# B6x register map
Vendor: XiaoMan; Series: B6 SOC; File version: 20260307
CPU: CM0+ r0p0, little endian, no MPU, no FPU, 2 interrupt priority bits
Registers are 32-bit, read-write, reset 0x0 unless marked. A register's access mark holds for its fields unless they carry their own. Offsets are from the block's base; [hi:lo] are bit positions.

## RCC — Reset and Clock Control
Base 0x40000000
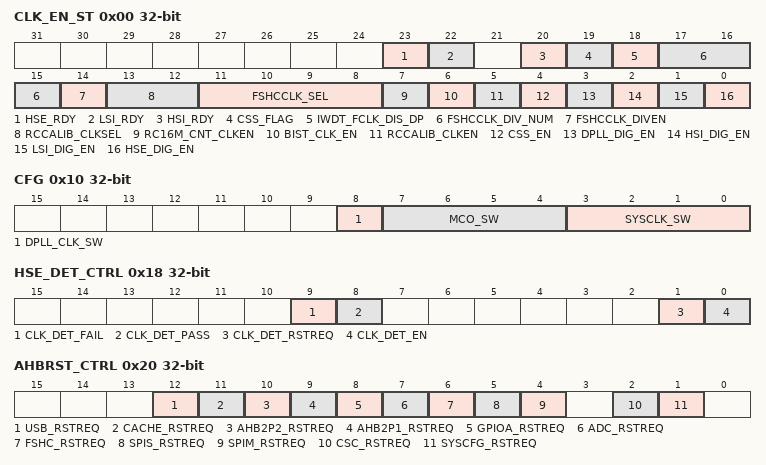
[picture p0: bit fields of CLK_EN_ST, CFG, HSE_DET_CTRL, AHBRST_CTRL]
0x00 CLK_EN_ST
  [23] HSE_RDY
  [22] LSI_RDY
  [20] HSI_RDY
  [19] CSS_FLAG
  [18] IWDT_FCLK_DIS_DP — disable the IWDT function clock (RC32K clock) when chip is in DeepSleep
  [17:15] FSHCCLK_DIV_NUM — div clock = dpll_128m/(fshcclk_div_num + 1)
  [14] FSHCCLK_DIVEN
  [13:12] RCCALIB_CLKSEL
  [11:8] FSHCCLK_SEL — fshc clock source select
  [7] RC16M_CNT_CLKEN
  [6] BIST_CLK_EN
  [5] RCCALIB_CLKEN
  [4] CSS_EN — HSE stable check enable
  [3] DPLL_DIG_EN
  [2] HSI_DIG_EN
  [1] LSI_DIG_EN
  [0] HSE_DIG_EN
0x04 AHBCLK_DIV — ahb_clk = sys_clk/(ahbclk_div+1)
0x08 APB1CLK_DIV — apb1_clk = ahb_clk/(apb1clk_div+1)
0x0C APB2CLK_DIV — apb2_clk = ahb_clk/(apb2clk_div+1)
0x10 CFG
  [8] DPLL_CLK_SW — 0:DPLL clock is use 64M, 1:DPLL clock is use 48M
  [7:4] MCO_SW — clock out source select
  [3:0] SYSCLK_SW — system clock source select
0x14 STCALIB
0x18 HSE_DET_CTRL
  [9] CLK_DET_FAIL
  [8] CLK_DET_PASS
  [1] CLK_DET_RSTREQ — reset the HSE clock detect module
  [0] CLK_DET_EN — HSE clock detect enable
0x1C CHIP_RSTREQ
0x20 AHBRST_CTRL
  [12] USB_RSTREQ, [11] CACHE_RSTREQ, [10] AHB2P2_RSTREQ, [9] AHB2P1_RSTREQ, [8] GPIOA_RSTREQ, [7] ADC_RSTREQ, [6] FSHC_RSTREQ, [5] SPIS_RSTREQ, [4] SPIM_RSTREQ, [2] CSC_RSTREQ, [1] SYSCFG_RSTREQ
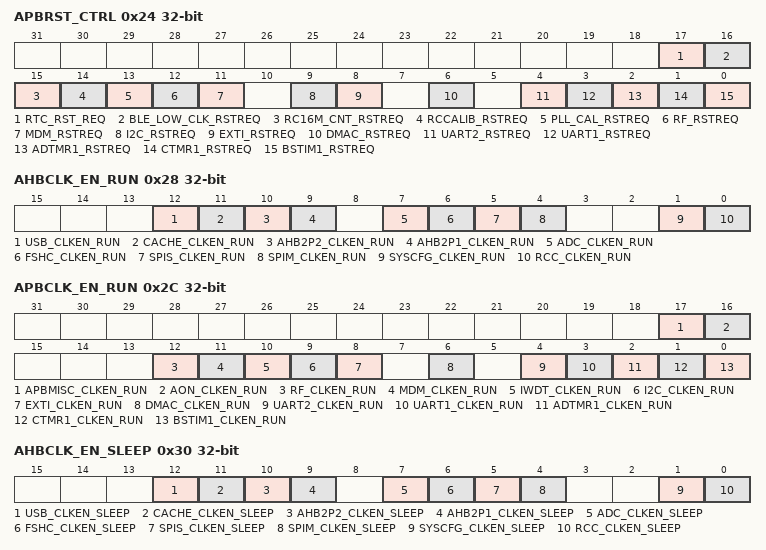
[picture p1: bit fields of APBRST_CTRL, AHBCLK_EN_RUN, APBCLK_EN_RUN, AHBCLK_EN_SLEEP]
0x24 APBRST_CTRL — AHBRST_CTRL register
  [17] RTC_RST_REQ, [16] BLE_LOW_CLK_RSTREQ, [15] RC16M_CNT_RSTREQ, [14] RCCALIB_RSTREQ, [13] PLL_CAL_RSTREQ, [12] RF_RSTREQ, [11] MDM_RSTREQ, [9] I2C_RSTREQ, [8] EXTI_RSTREQ, [6] DMAC_RSTREQ, [4] UART2_RSTREQ, [3] UART1_RSTREQ, [2] ADTMR1_RSTREQ, [1] CTMR1_RSTREQ, [0] BSTIM1_RSTREQ
0x28 AHBCLK_EN_RUN
  [12] USB_CLKEN_RUN, [11] CACHE_CLKEN_RUN, [10] AHB2P2_CLKEN_RUN, [9] AHB2P1_CLKEN_RUN, [7] ADC_CLKEN_RUN, [6] FSHC_CLKEN_RUN, [5] SPIS_CLKEN_RUN, [4] SPIM_CLKEN_RUN, [1] SYSCFG_CLKEN_RUN, [0] RCC_CLKEN_RUN
0x2C APBCLK_EN_RUN
  [17] APBMISC_CLKEN_RUN, [16] AON_CLKEN_RUN, [12] RF_CLKEN_RUN, [11] MDM_CLKEN_RUN, [10] IWDT_CLKEN_RUN, [9] I2C_CLKEN_RUN, [8] EXTI_CLKEN_RUN, [6] DMAC_CLKEN_RUN, [4] UART2_CLKEN_RUN, [3] UART1_CLKEN_RUN, [2] ADTMR1_CLKEN_RUN, [1] CTMR1_CLKEN_RUN, [0] BSTIM1_CLKEN_RUN
0x30 AHBCLK_EN_SLEEP
  [12] USB_CLKEN_SLEEP, [11] CACHE_CLKEN_SLEEP, [10] AHB2P2_CLKEN_SLEEP, [9] AHB2P1_CLKEN_SLEEP, [7] ADC_CLKEN_SLEEP, [6] FSHC_CLKEN_SLEEP, [5] SPIS_CLKEN_SLEEP, [4] SPIM_CLKEN_SLEEP, [1] SYSCFG_CLKEN_SLEEP, [0] RCC_CLKEN_SLEEP
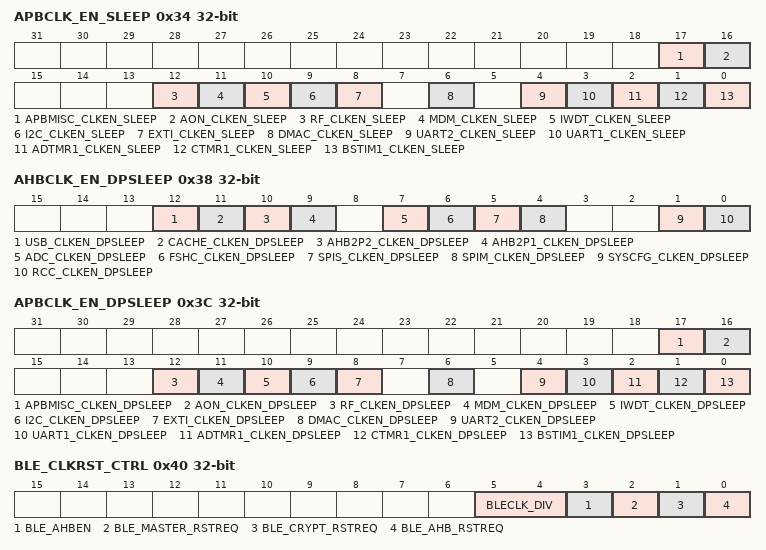
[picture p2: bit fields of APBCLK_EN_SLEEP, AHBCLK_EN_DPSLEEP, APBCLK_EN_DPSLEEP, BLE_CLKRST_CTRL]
0x34 APBCLK_EN_SLEEP
  [17] APBMISC_CLKEN_SLEEP, [16] AON_CLKEN_SLEEP, [12] RF_CLKEN_SLEEP, [11] MDM_CLKEN_SLEEP, [10] IWDT_CLKEN_SLEEP, [9] I2C_CLKEN_SLEEP, [8] EXTI_CLKEN_SLEEP, [6] DMAC_CLKEN_SLEEP, [4] UART2_CLKEN_SLEEP, [3] UART1_CLKEN_SLEEP, [2] ADTMR1_CLKEN_SLEEP, [1] CTMR1_CLKEN_SLEEP, [0] BSTIM1_CLKEN_SLEEP
0x38 AHBCLK_EN_DPSLEEP
  [12] USB_CLKEN_DPSLEEP, [11] CACHE_CLKEN_DPSLEEP, [10] AHB2P2_CLKEN_DPSLEEP, [9] AHB2P1_CLKEN_DPSLEEP, [7] ADC_CLKEN_DPSLEEP, [6] FSHC_CLKEN_DPSLEEP, [5] SPIS_CLKEN_DPSLEEP, [4] SPIM_CLKEN_DPSLEEP, [1] SYSCFG_CLKEN_DPSLEEP, [0] RCC_CLKEN_DPSLEEP
0x3C APBCLK_EN_DPSLEEP
  [17] APBMISC_CLKEN_DPSLEEP, [16] AON_CLKEN_DPSLEEP, [12] RF_CLKEN_DPSLEEP, [11] MDM_CLKEN_DPSLEEP, [10] IWDT_CLKEN_DPSLEEP, [9] I2C_CLKEN_DPSLEEP, [8] EXTI_CLKEN_DPSLEEP, [6] DMAC_CLKEN_DPSLEEP, [4] UART2_CLKEN_DPSLEEP, [3] UART1_CLKEN_DPSLEEP, [2] ADTMR1_CLKEN_DPSLEEP, [1] CTMR1_CLKEN_DPSLEEP, [0] BSTIM1_CLKEN_DPSLEEP
0x40 BLE_CLKRST_CTRL
  [5:4] BLECLK_DIV, [3] BLE_AHBEN, [2] BLE_MASTER_RSTREQ, [1] BLE_CRYPT_RSTREQ, [0] BLE_AHB_RSTREQ
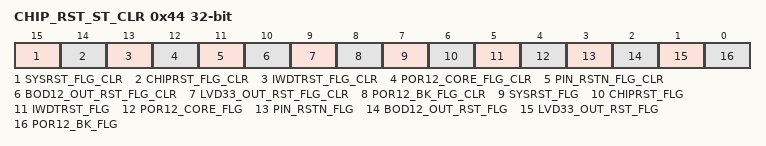
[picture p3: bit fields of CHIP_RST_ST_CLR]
0x44 CHIP_RST_ST_CLR
  [15] SYSRST_FLG_CLR, [14] CHIPRST_FLG_CLR, [13] IWDTRST_FLG_CLR, [12] POR12_CORE_FLG_CLR, [11] PIN_RSTN_FLG_CLR, [10] BOD12_OUT_RST_FLG_CLR, [9] LVD33_OUT_RST_FLG_CLR, [8] POR12_BK_FLG_CLR, [7] SYSRST_FLG, [6] CHIPRST_FLG, [5] IWDTRST_FLG, [4] POR12_CORE_FLG, [3] PIN_RSTN_FLG, [2] BOD12_OUT_RST_FLG, [1] LVD33_OUT_RST_FLG, [0] POR12_BK_FLG
